# nrf51 register map
Vendor: Nordic Semiconductor; Series: nrf51; File version: 522
CPU: CM0 r3p1, little endian, no MPU, no FPU, 2 interrupt priority bits
Registers are 32-bit, read-write, reset 0x0 unless marked. A register's access mark holds for its fields unless they carry their own. Offsets are from the block's base; [hi:lo] are bit positions; {n}, {i} and the like mark numbered series.

## POWER — Power Control.
Base 0x40000000
0x78 TASKS_CONSTLAT wo — Enable constant latency mode.
0x7C TASKS_LOWPWR wo — Enable low power mode (variable latency).
0x108 EVENTS_POFWARN — Power failure warning.
0x304 INTENSET — Interrupt enable set register.
  [2] POFWARN — Enable interrupt on POFWARN event.
    on read: 0=Disabled (Interrupt disabled.); 1=Enabled (Interrupt enabled.) | on write: 1=Set (Enable interrupt on write.)
0x308 INTENCLR — Interrupt enable clear register.
  [2] POFWARN — Disable interrupt on POFWARN event.
    on read: 0=Disabled (Interrupt disabled.); 1=Enabled (Interrupt enabled.) | on write: 1=Clear (Disable interrupt on write.)
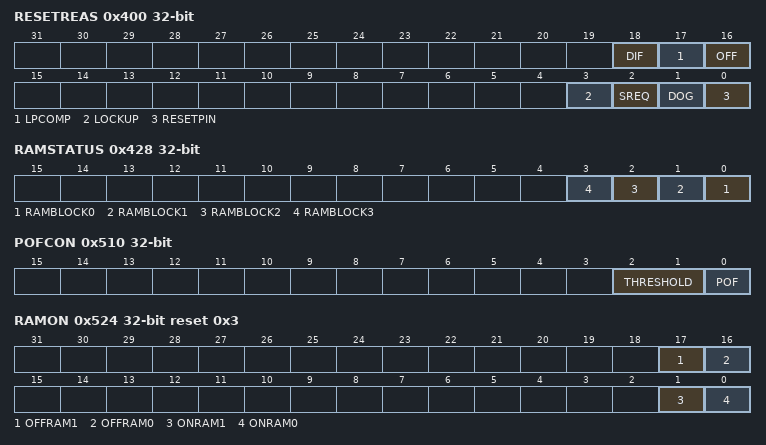
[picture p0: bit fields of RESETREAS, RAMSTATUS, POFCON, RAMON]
0x400 RESETREAS — Reset reason.
  [all] fields
    0=NotDetected (Reset not detected.); 1=Detected (Reset detected.)
  [18] DIF — Reset from wake-up from OFF mode detected by entering into debug interface mode.
  [17] LPCOMP — Reset from wake-up from OFF mode detected by the use of ANADETECT signal from LPCOMP.
  [16] OFF — Reset from wake-up from OFF mode detected by the use of DETECT signal from GPIO.
  [3] LOCKUP — Reset from CPU lock-up detected.
  [2] SREQ — Reset from AIRCR.SYSRESETREQ detected.
  [1] DOG — Reset from watchdog detected.
  [0] RESETPIN — Reset from pin-reset detected.
0x428 RAMSTATUS ro
  [n] RAMBLOCK{n} (n=0..3) — RAM block {n} status.
    0=Off (RAM block {n} is off or powering up.); 1=On (RAM block {n} is on.)
0x500 SYSTEMOFF wo
  [0] SYSTEMOFF — Enter system off mode.
    1=Enter system off mode
0x510 POFCON — Power failure configuration.
  [2:1] THRESHOLD — Set threshold level.
    0=V21 (Set threshold to 2.1Volts.); 1=V23 (Set threshold to 2.3Volts.); 2=V25 (Set threshold to 2.5Volts.); 3=V27 (Set threshold to 2.7Volts.)
  [0] POF — Power failure comparator enable.
    0=Disabled; 1=Enabled
0x51C GPREGRET — General purpose retention register. This register is a retained register.
  [7:0] GPREGRET — General purpose retention register.
0x524 RAMON reset 0x3 — Ram on/off.
  [17] OFFRAM1 — RAM block 1 behaviour in OFF mode.
    0=RAM1Off (RAM block 1 OFF in OFF mode.); 1=RAM1On (RAM block 1 ON in OFF mode.)
  [16] OFFRAM0 — RAM block 0 behaviour in OFF mode.
    0=RAM0Off (RAM block 0 OFF in OFF mode.); 1=RAM0On (RAM block 0 ON in OFF mode.)
  [1] ONRAM1 — RAM block 1 behaviour in ON mode.
    0=RAM1Off (RAM block 1 OFF in ON mode.); 1=RAM1On (RAM block 1 ON in ON mode.)
  [0] ONRAM0 — RAM block 0 behaviour in ON mode.
    0=RAM0Off (RAM block 0 OFF in ON mode.); 1=RAM0On (RAM block 0 ON in ON mode.)
0x544 RESET — Pin reset functionality configuration register. This register is a retained register.
  [0] RESET — Enable or disable pin reset in debug interface mode.
    0=Disabled (Pin reset in debug interface mode disabled.); 1=Enabled (Pin reset in debug interface mode enabled.)
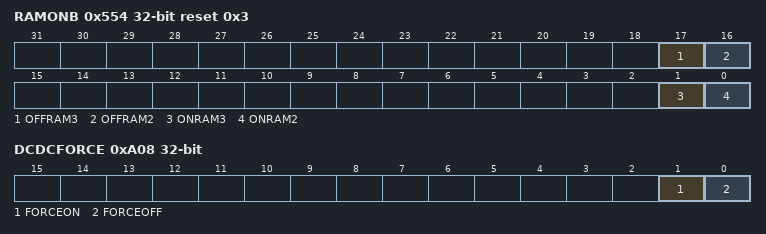
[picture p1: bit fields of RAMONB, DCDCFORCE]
0x554 RAMONB reset 0x3 — Ram on/off.
  [17] OFFRAM3 — RAM block 3 behaviour in OFF mode.
    0=RAM3Off (RAM block 3 OFF in OFF mode.); 1=RAM3On (RAM block 3 ON in OFF mode.)
  [16] OFFRAM2 — RAM block 2 behaviour in OFF mode.
    0=RAM2Off (RAM block 2 OFF in OFF mode.); 1=RAM2On (RAM block 2 ON in OFF mode.)
  [1] ONRAM3 — RAM block 3 behaviour in ON mode.
    0=RAM3Off (RAM block 33 OFF in ON mode.); 1=RAM3On (RAM block 3 ON in ON mode.)
  [0] ONRAM2 — RAM block 2 behaviour in ON mode.
    0=RAM2Off (RAM block 2 OFF in ON mode.); 1=RAM2On (RAM block 2 ON in ON mode.)
0x578 DCDCEN — DCDC converter enable configuration register.
  [0] DCDCEN — Enable DCDC converter.
    0=Disabled (DCDC converter disabled.); 1=Enabled (DCDC converter enabled.)
0xA08 DCDCFORCE — DCDC power-up force register.
  [1] FORCEON — DCDC power-up force on.
    0=NoForce; 1=Force
  [0] FORCEOFF — DCDC power-up force off.
    0=NoForce; 1=Force

## Notices in the file
Copyright (c) 2010 - 2024, Nordic Semiconductor ASA
All rights reserved.
Redistribution and use in source and binary forms, with or without modification,
are permitted provided that the following conditions are met:
1. Redistributions of source code must retain the above copyright notice, this
list of conditions and the following disclaimer.
2. Redistributions in binary form, except as embedded into a Nordic
Semiconductor ASA integrated circuit in a product or a software update for
such product, must reproduce the above copyright notice, this list of
conditions and the following disclaimer in the documentation and/or other
materials provided with the distribution.
3. Neither the name of Nordic Semiconductor ASA nor the names of its
contributors may be used to endorse or promote products derived from this
software without specific prior written permission.
4. This software, with or without modification, must only be used with a
Nordic Semiconductor ASA integrated circuit.
5. Any software provided in binary form under this license must not be reverse
engineered, decompiled, modified and/or disassembled.
THIS SOFTWARE IS PROVIDED BY NORDIC SEMICONDUCTOR ASA "AS IS" AND ANY EXPRESS
OR IMPLIED WARRANTIES, INCLUDING, BUT NOT LIMITED TO, THE IMPLIED WARRANTIES
OF MERCHANTABILITY, NONINFRINGEMENT, AND FITNESS FOR A PARTICULAR PURPOSE ARE
DISCLAIMED. IN NO EVENT SHALL NORDIC SEMICONDUCTOR ASA OR CONTRIBUTORS BE
LIABLE FOR ANY DIRECT, INDIRECT, INCIDENTAL, SPECIAL, EXEMPLARY, OR
CONSEQUENTIAL DAMAGES (INCLUDING, BUT NOT LIMITED TO, PROCUREMENT OF SUBSTITUTE
GOODS OR SERVICES; LOSS OF USE, DATA, OR PROFITS; OR BUSINESS INTERRUPTION)
HOWEVER CAUSED AND ON ANY THEORY OF LIABILITY, WHETHER IN CONTRACT, STRICT
LIABILITY, OR TORT (INCLUDING NEGLIGENCE OR OTHERWISE) ARISING IN ANY WAY OUT
OF THE USE OF THIS SOFTWARE, EVEN IF ADVISED OF THE POSSIBILITY OF SUCH DAMAGE.
